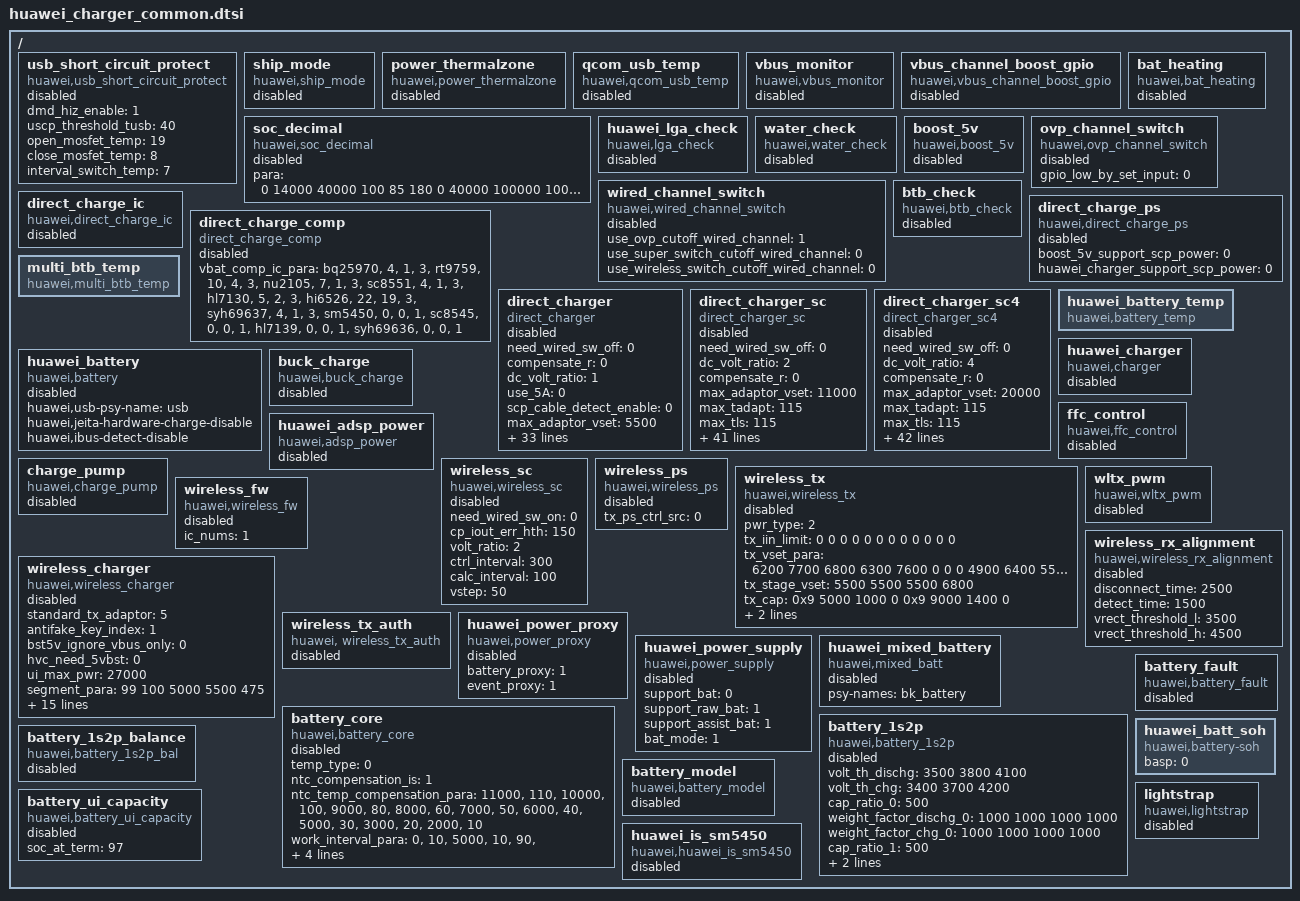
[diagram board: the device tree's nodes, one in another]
/{
	usb_short_circuit_protect: usb_short_circuit_protect {
		compatible = "huawei,usb_short_circuit_protect";
		dmd_hiz_enable = <1>;
		uscp_threshold_tusb = <40>;
		open_mosfet_temp = <19>;
		close_mosfet_temp = <8>;
		interval_switch_temp = <7>;
		status = "disabled";
	};

	ship_mode: ship_mode {
		compatible = "huawei,ship_mode";
		status = "disabled";
	};

	power_thermalzone: power_thermalzone {
		compatible = "huawei,power_thermalzone";
		status = "disabled";
	};

	qcom_usb_temp: qcom_usb_temp {
		compatible = "huawei,qcom_usb_temp";
		status = "disabled";
	};

	vbus_monitor: vbus_monitor {
		compatible = "huawei,vbus_monitor";
		status = "disabled";
	};

	vbus_channel_boost_gpio: vbus_channel_boost_gpio {
		compatible = "huawei,vbus_channel_boost_gpio";
		status = "disabled";
	};

	bat_heating: bat_heating {
		compatible = "huawei,bat_heating";
		status = "disabled";
	};

	soc_decimal: soc_decimal {
		compatible = "huawei,soc_decimal";
		para = <
				0 14000 40000  100 85  180
				0 40000 100000 100 120 100
				1 20000 27000  100 85  140
				1 27000 100000 100 85  140
		>;
		status = "disabled";
	};

	huawei_lga_check: huawei_lga_check {
		compatible = "huawei,lga_check";
		status = "disabled";
	};

	water_check: water_check {
		compatible = "huawei,water_check";
		status = "disabled";
	};

	boost_5v: boost_5v {
		compatible = "huawei,boost_5v";
		status = "disabled";
	};

	wired_channel_switch: wired_channel_switch {
		compatible = "huawei,wired_channel_switch";
		use_ovp_cutoff_wired_channel = <1>;
		use_super_switch_cutoff_wired_channel = <0>;
		use_wireless_switch_cutoff_wired_channel = <0>;
		status = "disabled";
	};

	ovp_channel_switch: ovp_channel_switch {
		compatible = "huawei,ovp_channel_switch";
		gpio_low_by_set_input = <0>;
		status = "disabled";
	};

	btb_check: btb_check {
		compatible = "huawei,btb_check";
		status = "disabled";
	};

	direct_charge_ps: direct_charge_ps {
		compatible = "huawei,direct_charge_ps";
		boost_5v_support_scp_power = <0>;
		huawei_charger_support_scp_power = <0>;
		status = "disabled";
	};

	direct_charge_ic: direct_charge_ic {
		compatible = "huawei,direct_charge_ic";
		/* The IC_PARA table is used to find the relationship between chip and path */
		/* the chip's current passing capacity */
		/* and the sampling points of battery voltage and current */
		/* ic_index path_index max_ibat ibat_sample_point vbat_sample_point */
		status = "disabled";
	};

	direct_charge_comp: direct_charge_comp {
		compatible = "direct_charge_comp";
		/* The vbat_comp_ic_para table is used to get the chip's leakage current feature */
		/* of the positive and negative and supported compensation modes */
		/* ic_name leak_curr_p leak_curr_n comp_mode */
		vbat_comp_ic_para =
			"bq25970", "4", "1", "3",
			"rt9759", "10", "4", "3",
			"nu2105", "7", "1", "3",
			"sc8551", "4", "1", "3",
			"hl7130", "5", "2", "3",
			"hi6526", "22", "19", "3",
			"syh69637", "4", "1", "3",
			"sm5450", "0", "0", "1",
			"sc8545", "0", "0", "1",
			"hl7139", "0", "0", "1",
			"syh69636", "0", "0", "1";
		/* The vbat_samp_point_para table is used to find the comp relationship between chips */
		/* Calculate all compensation values of the same index */
		/* as the final compensation of the chip */
		/* Separately calculate positive and negative poles */
		/* ic_index  p_index  n_index */
		status = "disabled";
	};

	direct_charger: direct_charger {
		need_wired_sw_off = <0>;
		compensate_r = <0>;
		dc_volt_ratio = <1>;
		use_5A = <0>;
		scp_cable_detect_enable = <0>;
		max_adaptor_vset = <5500>;
		max_tadapt = <115>;
		max_tls = <115>;
		ibat_abnormal_th = <200>;
		first_cc_stage_timer_in_min = <0>;
		max_dc_bat_vol = <4350>;
		min_dc_bat_vol = <3550>;
		charge_control_interval = <5>;
		threshold_caculation_interval = <5>;
		safety_monitor_interval = <5>;
		scp_work_on_charger = <0>;
		init_adapter_vset = <4400>;
		init_delt_vset = <300>;
		vstep = <10>;
		delta_err = <200>;
		vol_err_th = <150>;
		full_path_res_max = <120>;
		standard_cable_full_path_res_max = <160>;
		ctc_cable_full_path_res_max = <320>;
		max_current_for_ctc_cable = <3250>;
		max_current_for_none_standard_cable = <3000>;
		super_ico_current = <4000>;
		is_show_ico_first = <0>;
		adaptor_leakage_current_th = <300>;
		adaptor_detect_by_voltage = <0>;
		stage_need_to_jump = "-1";
		startup_iin_limit = <1500>;
		adp_qtr_a_10v2p25a_cur_para =
			"-32767", "5500",  "4000",
			"5500",   "9000",  "2500",
			"9000",   "10000", "2250",
			"10000",  "10500", "2000",
			"10500",  "32767", "1500";
		adp_qtr_c_20v3a_cur_para =
			"-32767", "10300", "4000",
			"10300",  "32767", "3000";
		temp_para =
			"-32767", "10", "0",
			"10", "45", "4750",
			"45", "32767", "0";
		compatible = "direct_charger";
		status = "disabled";
	};

	direct_charger_sc: direct_charger_sc {
		compatible = "direct_charger_sc";
		need_wired_sw_off = <0>;
		dc_volt_ratio = <2>;
		compensate_r = <0>;
		max_adaptor_vset = <11000>;
		max_tadapt = <115>;
		max_tls = <115>;
		ibat_abnormal_th = <200>;
		first_cc_stage_timer_in_min = <0>;
		max_dc_bat_vol = <4380>;
		min_dc_bat_vol = <3550>;
		charge_control_interval = <5>;
		threshold_caculation_interval = <5>;
		safety_monitor_interval = <5>;
		scp_work_on_charger = <0>;
		init_adapter_vset = <8800>;
		init_delt_vset = <600>;
		vstep = <20>;
		delta_err = <300>;
		vol_err_th = <150>;
		full_path_res_max = <120>;
		standard_cable_full_path_res_max = <160>;
		ctc_cable_full_path_res_max = <320>;
		max_current_for_ctc_cable = <6500>;
		max_current_for_none_standard_cable = <6000>;
		super_ico_current = <4000>;
		is_show_ico_first = <0>;
		adaptor_leakage_current_th = <300>;
		adaptor_detect_by_voltage = <0>;
		gain_curr_10v2a = <300>;
		stage_need_to_jump = "-1";
		startup_iin_limit = <1500>;
		product_max_pwr = <40000>;
		adaptor_antifake_execute_enable = <1>;
		temp_para =
			"-32767", "10", "0",
			"10", "45", "4750",
			"45", "32767", "0";
		10v2p25a_cur_para =
			"-32767", "5500",  "2000",
			"5500",   "9000",  "2500",
			"9000",   "10000", "2250",
			"10000",  "10500", "2000",
			"10500",  "32767", "1500";
		10v2p25a_car_cur_para =
			"-32767", "5500",  "2000",
			"5500",   "9000",  "2500",
			"9000",   "10000", "2250",
			"10000",  "32767", "2000";
		adp_qtr_a_10v2p25a_cur_para =
			"-32767", "5500",  "4000",
			"5500",   "9000",  "2500",
			"9000",   "10000", "2250",
			"10000",  "10500", "2000",
			"10500",  "32767", "1500";
		adp_qtr_c_20v3a_cur_para =
			"-32767", "10300", "4000",
			"10300",  "32767", "3000";
		10v4a_cur_para =
			"-32767", "11000", "4000";
		status = "disabled";
	};

	direct_charger_sc4: direct_charger_sc4 {
		compatible = "direct_charger_sc4";
		need_wired_sw_off = <0>;
		dc_volt_ratio = <4>;
		compensate_r = <0>;
		max_adaptor_vset = <20000>;
		max_tadapt = <115>;
		max_tls = <115>;
		ibat_abnormal_th = <200>;
		first_cc_stage_timer_in_min = <0>;
		max_dc_bat_vol = <4380>;
		min_dc_bat_vol = <3550>;
		charge_control_interval = <5>;
		threshold_caculation_interval = <5>;
		safety_monitor_interval = <5>;
		scp_work_on_charger = <0>;
		init_adapter_vset = <15000>;
		init_delt_vset = <800>;
		vstep = <40>;
		delta_err = <400>;
		vol_err_th = <150>;
		full_path_res_max = <120>;
		standard_cable_full_path_res_max = <160>;
		ctc_cable_full_path_res_max = <320>;
		max_current_for_ctc_cable = <13000>;
		max_current_for_none_standard_cable = <12000>;
		super_ico_current = <4000>;
		is_show_ico_first = <0>;
		adaptor_leakage_current_th = <300>;
		adaptor_detect_by_voltage = <0>;
		gain_curr_10v2a = <300>;
		stage_need_to_jump = "-1";
		startup_iin_limit = <1500>;
		product_max_pwr = <40000>;
		adaptor_antifake_execute_enable = <1>;
		temp_para =
			"-32767", "10", "0",
			"10", "45", "4750",
			"45", "32767", "0";
		10v2p25a_cur_para =
			"-32767", "5500",  "2000",
			"5500",   "9000",  "2500",
			"9000",   "10000", "2250",
			"10000",  "10500", "2000",
			"10500",  "32767", "1500";
		10v2p25a_car_cur_para =
			"-32767", "5500",  "2000",
			"5500",   "9000",  "2500",
			"9000",   "10000", "2250",
			"10000",  "32767", "2000";
		adp_qtr_a_10v2p25a_cur_para =
			"-32767", "5500",  "4000",
			"5500",   "9000",  "2500",
			"9000",   "10000", "2250",
			"10000",  "10500", "2000",
			"10500",  "32767", "1500";
		adp_qtr_c_20v3a_cur_para =
			"-32767", "10300", "4000",
			"10300",  "32767", "3000";
		10v4a_cur_para =
			"-32767", "11000", "4000";
		20v3p25a_cur_para =
			"-32767", "20000", "3250";
		status = "disabled";
	};

	huawei_battery_temp: huawei_battery_temp {
		compatible = "huawei,battery_temp";
		status = "ok";
	};
	multi_btb_temp: multi_btb_temp {
		compatible = "huawei,multi_btb_temp";
		status = "ok";
	};
	huawei_battery: huawei_battery {
		compatible = "huawei,battery";
		huawei,usb-psy-name = "usb";
		huawei,jeita-hardware-charge-disable;
		huawei,ibus-detect-disable;
		status = "disabled";
	};

	huawei_charger: huawei_charger {
		compatible = "huawei,charger";
		status = "disabled";
	};

	buck_charge: buck_charge {
		compatible = "huawei,buck_charge";
		status = "disabled";
	};

	ffc_control: ffc_control {
		compatible = "huawei,ffc_control";
		status = "disabled";
	};

	huawei_adsp_power: huawei_adsp_power {
		compatible = "huawei,adsp_power";
		status = "disabled";
	};

	charge_pump: charge_pump {
		compatible = "huawei,charge_pump";
		status = "disabled";
	};

	wireless_sc: wireless_sc {
		compatible = "huawei,wireless_sc";
		need_wired_sw_on = <0>;
		cp_iout_err_hth = <150>;
		volt_ratio = <2>;
		ctrl_interval = <300>;
		calc_interval = <100>;
		vstep = <50>;
		status = "disabled";
	};

	wireless_ps: wireless_ps {
		compatible = "huawei,wireless_ps";
		tx_ps_ctrl_src = <0>; /* 0:NA 1:tx_chip 2:AP */
		status = "disabled";
	};

	wireless_tx: wireless_tx {
		compatible = "huawei,wireless_tx";
		pwr_type = <2>; //0:VBUS_OTG 1:5VBST_OTG 2:SP-BST
		tx_iin_limit = <0 0 0 0 0 0 0 0 0 0 0 0>;
		/* rx_vmin rx_vmax tx_vset tx_lvset tx_hvset tx_pl_th tx_pl_cnt ext_hdl */
		tx_vset_para = <
			6200 7700 6800 6300 7600 0 0 0
			4900 6400 5500 5000 6300 0 0 0
			8500 10900 10000 9500 10800 0 0 0
		>;
		/* power_supply ping handshake default */
		tx_stage_vset = <5500 5500 5500 6800>;
		/* type vout iout extra */
		tx_cap = <
			0x9 5000 1000 0
			0x9 9000 1400 0
		>;
		tx_vset_tbat_high = <45>;
		tx_vset_tbat_low = <40>;
		status = "disabled";
	};

	wltx_pwm: wltx_pwm {
		compatible = "huawei,wltx_pwm";
		status = "disabled";
	};

	wireless_fw: wireless_fw {
		compatible = "huawei,wireless_fw";
		ic_nums = <1>;
		status = "disabled";
	};

	wireless_rx_alignment: wireless_rx_alignment {
		compatible = "huawei,wireless_rx_alignment";
		disconnect_time = <2500>;
		detect_time = <1500>;
		vrect_threshold_l = <3500>;
		vrect_threshold_h = <4500>;
		status = "disabled";
	};

	wireless_charger: wireless_charger {
		compatible = "huawei,wireless_charger";
		standard_tx_adaptor = <5>;/*fcp*/
		antifake_key_index = <1>;
		bst5v_ignore_vbus_only = <0>;
		hvc_need_5vbst = <0>;
		ui_max_pwr = <27000>;
		segment_para = <
			99 100 5000 5500 475
		>;
		rx_vout_err_ratio = <81>; /*percent*/
		rx_iout_min = <130>;
		rx_iout_step = <350>;
		rx_iout_ctrl_para = <
			0     80    130
			80    150   300
			150   250   400
			250   325   475
			325   450   600
			450   550   700
			550   675   825
			675   850   1000
			850   9999  1100
		>;
		product_para = <
			15000 18000 1600
		>;
		tx_prop =
			"0x01", "SDP",     "0", "0", "5000", "475",
			"0x02", "CDP",     "0", "0", "5000", "1000",
			"0x03", "NON_STD", "0", "0", "5000", "1000",
			"0x04", "DCP",     "0", "0", "5000", "1000",
			"0x05", "FCP",     "0", "1", "9000", "2000",
			"0x06", "SCP",     "0", "1", "5000", "1000",
			"0x07", "PD",      "0", "1", "5000", "1000",
			"0x08", "QC",      "0", "1", "5000", "1000",
			"0x09", "OTG_A",   "0", "0", "5000", "475",
			"0x0A", "OTG_B",   "0", "0", "5000", "475",
			"0xff", "ERR",     "0", "0", "5000", "1000";
		volt_mode = <
			0 5000
			1 9000
			2 12000
			3 15000
		>;
		status = "disabled";
	};

	wireless_tx_auth: wireless_tx_auth {
		compatible = "huawei, wireless_tx_auth";
		status = "disabled";
	};

	huawei_power_proxy: huawei_power_proxy {
		compatible = "huawei,power_proxy";
		battery_proxy = <1>;
		event_proxy = <1>;
		status = "disabled";
	};

	huawei_power_supply: huawei_power_supply {
		compatible = "huawei,power_supply";
		support_bat = <0>;
		support_raw_bat = <1>;
		support_assist_bat = <1>;
		bat_mode = <1>;
		status = "disabled";
	};

	huawei_mixed_battery: huawei_mixed_battery {
		compatible = "huawei,mixed_batt";
		psy-names = "bk_battery";
		status = "disabled";
	};

	battery_core: battery_core {
		compatible = "huawei,battery_core";
		temp_type = <0>;
		ntc_compensation_is = <1>;
		ntc_temp_compensation_para =
			"11000", "110",
			"10000", "100",
			"9000", "80",
			"8000", "60",
			"7000", "50",
			"6000", "40",
			"5000", "30",
			"3000", "20",
			"2000", "10";
		work_interval_para =
			"0","10","5000",
			"10","90","10000",
			"90","100","30000";
			voltage_now_scale = <1000>;
			voltage_max_scale = <1000>;
			charge_fcc_scale = <1000>;
			status = "disabled";
	};

	battery_1s2p: battery_1s2p {
		compatible = "huawei,battery_1s2p";
		volt_th_dischg = <3500 3800 4100>;
		volt_th_chg = <3400 3700 4200>;

		cap_ratio_0 = <500>;
		weight_factor_dischg_0 =  <1000 1000 1000 1000>;
		weight_factor_chg_0 =  <1000 1000 1000 1000>;

		cap_ratio_1 = <500>;
		weight_factor_dischg_1 =  <1000 1000 1000 1000>;
		weight_factor_chg_1 =  <1000 1000 1000 1000>;
		status = "disabled";
	};

	battery_1s2p_balance: battery_1s2p_balance {
		compatible = "huawei,battery_1s2p_bal";
		status = "disabled";
	};

	battery_fault: battery_fault {
		compatible = "huawei,battery_fault";
		status = "disabled";
	};

	battery_model: battery_model {
		compatible = "huawei,battery_model";
		status = "disabled";
	};

	battery_ui_capacity: battery_ui_capacity {
		compatible = "huawei,battery_ui_capacity";
		soc_at_term = <97>;
		status = "disabled";
	};

	huawei_batt_soh: huawei_batt_soh {
		compatible = "huawei,battery-soh";
		basp = <0>;
		status = "ok";
	};

	lightstrap: lightstrap {
		compatible = "huawei,lightstrap";
                status = "disabled";
	};

	huawei_is_sm5450: huawei_is_sm5450 {
		compatible = "huawei,huawei_is_sm5450";
		status = "disabled";
	};
};
